VERSION ""

NS_ :

BS_:

BU_: XXX

BO_ 32 NEW_MSG_1: 8 XXX
 SG_ NEW_SIGNAL_1 : 47|16@0+ (1,0) [0|65535] "" XXX

BO_ 1136 NEW_MSG_2: 8 XXX

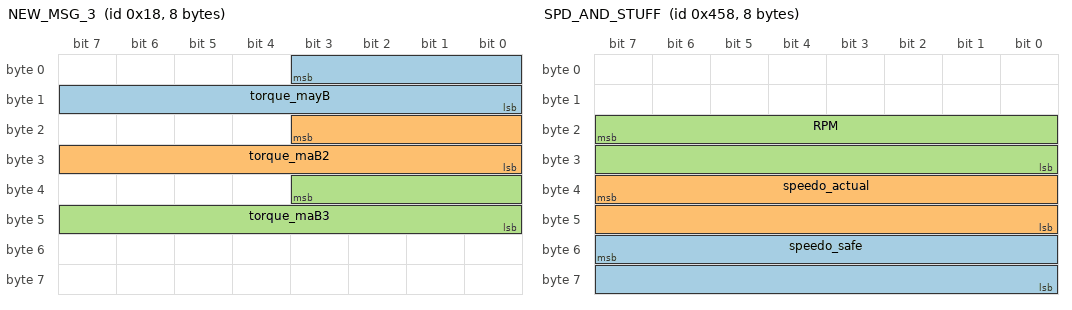
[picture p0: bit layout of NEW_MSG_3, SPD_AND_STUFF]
BO_ 24 NEW_MSG_3: 8 XXX
 SG_ torque_mayB : 3|12@0+ (1,0) [0|65535] "" XXX
 SG_ torque_maB2 : 19|12@0+ (1,0) [0|65535] "" XXX
 SG_ torque_maB3 : 35|12@0+ (1,0) [0|65535] "" XXX

BO_ 60 NEW_MSG_4: 8 XXX
 SG_ NEW_SIGNAL_1 : 7|64@0+ (1,0) [0|18446744073709552000] "" XXX

BO_ 16 NEW_MSG_5: 8 XXX
 SG_ binary1 : 55|8@0+ (1,0) [0|16777215] "" XXX

BO_ 104 NEW_MSG_6: 8 XXX
 SG_ NEW_SIGNAL_1 : 22|29@0+ (1,0) [0|255] "" XXX

BO_ 8 NEW_MSG_7: 8 XXX
 SG_ NEW_SIGNAL_1 : 53|4@0+ (1,0) [0|3] "" XXX

BO_ 56 NEW_MSG_8: 8 XXX
 SG_ NEW_SIGNAL_1 : 54|15@0+ (1,0) [0|16777215] "" XXX

BO_ 88 NEW_MSG_9: 8 XXX
 SG_ NEW_SIGNAL_1 : 7|8@0+ (1,0) [0|255] "" XXX

BO_ 1040 NEW_MSG_10: 8 XXX
 SG_ NEW_SIGNAL_1 : 63|8@0- (1,0) [0|255] "" XXX

BO_ 1072 NEW_MSG_11: 8 XXX
 SG_ NEW_SIGNAL_1 : 31|3@0+ (1,0) [0|65535] "" XXX

BO_ 1056 NEW_MSG_12: 8 XXX
 SG_ only_changes_when_car_moves : 7|64@0+ (0.001,0) [0|1099511627775] "" XXX

BO_ 1092 NEW_MSG_13: 8 XXX

BO_ 1080 NEW_MSG_14: 8 XXX
 SG_ NEW_SIGNAL_1 : 31|32@0+ (1,0) [0|1099511627775] "" XXX

BO_ 1096 NEW_MSG_15: 8 XXX
 SG_ NEW_SIGNAL_1 : 23|48@0+ (1,0) [0|16777215] "" XXX

BO_ 1112 SPD_AND_STUFF: 8 XXX
 SG_ speedo_safe : 55|16@0+ (0.01,0) [0|65535] "" XXX
 SG_ speedo_actual : 39|16@0+ (0.01,0) [0|65535] "kph" XXX
 SG_ RPM : 23|16@0- (0.8442,-20638) [0|65535] "RPM" XXX

BO_ 1120 NEW_MSG_16: 8 XXX
 SG_ NEW_SIGNAL_1 : 55|16@0+ (1,0) [0|65535] "" XXX

BO_ 1104 NEW_MSG_17: 8 XXX
 SG_ NEW_SIGNAL_1 : 7|64@0+ (1,0) [0|18446744073709552000] "" XXX

BO_ 1128 NEW_MSG_18: 8 XXX
 SG_ NEW_SIGNAL_1 : 24|8@1+ (1,0) [0|255] "" XXX

BO_ 1048 NEW_MSG_19: 8 XXX

BO_ 1064 NEW_MSG_20: 8 XXX

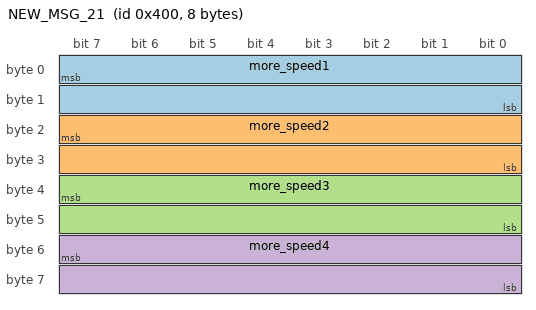
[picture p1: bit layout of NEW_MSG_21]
BO_ 1024 NEW_MSG_21: 8 XXX
 SG_ more_speed1 : 7|16@0+ (1,0) [0|255] "" XXX
 SG_ more_speed2 : 23|16@0+ (1,0) [0|65535] "" XXX
 SG_ more_speed3 : 39|16@0+ (1,0) [0|65535] "" XXX
 SG_ more_speed4 : 55|16@0+ (1,0) [0|65535] "" XXX
